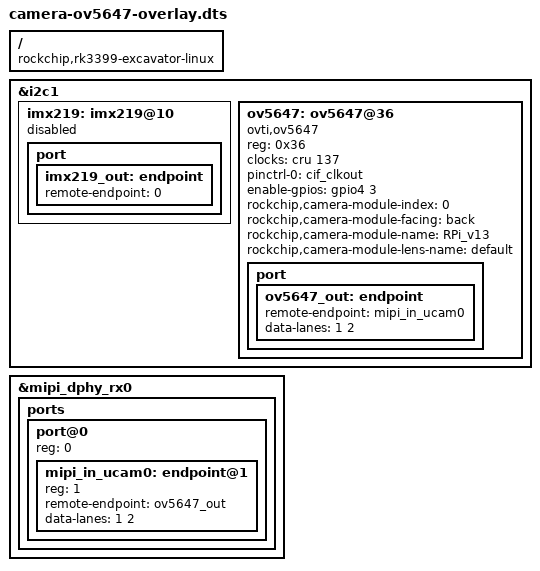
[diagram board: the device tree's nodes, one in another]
// Definitions for ds1307
/dts-v1/;
/plugin/;

/ {
	compatible = "rockchip,rk3399-excavator-linux", "rockchip,rk3399";

	fragment@0 {
		target = <&i2c1>;
		__overlay__ {
			status = "okay";

			imx219: imx219@10 {
				status = "disabled";
				port {
					imx219_out: endpoint {
						remote-endpoint = <0>;
					};
				};
			};

			ov5647: ov5647@36 {
				compatible = "ovti,ov5647";
				status = "okay";
				reg = <0x36>;
				clocks = <&cru 137>;
				clock-names = "xvclk";

				pinctrl-names = "rockchip,camera_default";
				pinctrl-0 = <&cif_clkout>;

				enable-gpios = <&gpio4 3 0>;

				rockchip,camera-module-index = <0>;
				rockchip,camera-module-facing = "back";
				rockchip,camera-module-name = "RPi_v13";
				rockchip,camera-module-lens-name = "default";

				port {
					ov5647_out: endpoint {
						remote-endpoint = <&mipi_in_ucam0>;
						data-lanes = <1 2>;
					};
				};
			};
		};
	};

	fragment@1 {
		target = <&mipi_dphy_rx0>;
		__overlay__ {
			status = "okay";

			ports {
				#address-cells = <1>;
				#size-cells = <0>;

				port@0 {
					reg = <0>;
					#address-cells = <1>;
					#size-cells = <0>;

					mipi_in_ucam0: endpoint@1 {
						reg = <1>;
						remote-endpoint = <&ov5647_out>;
						data-lanes = <1 2>;
					};
				};
			};
		};
	};
};
